# C2000_CLA_Type2_Registers register map
Vendor: Texas Instruments
Peripheral module from a debugger description file (folder C2000).
Address unit: 16 bits
Registers are 16-bit, access not given, reset 0x0 unless marked. A register's access mark holds for its fields unless they carry their own. Offsets are as the file gives them; lines under a group give offsets from that group; [hi:lo] are bit positions; {n}, {i} and the like mark numbered series; 'fields as' and 'values as' point back to an identical list; <NAME> marks a mode.

## CLA2 — CLA2 Registers
0x00 MVECT1 reset not defined — Task 1 vector
0x01 MVECT2 reset not defined — Task 2 vector
0x02 MVECT3 reset not defined — Task 3 vector
0x03 MVECT4 reset not defined — Task 4 vector
0x04 MVECT5 reset not defined — Task 5 vector
0x05 MVECT6 reset not defined — Task 6 vector
0x06 MVECT7 reset not defined — Task 7 vector
0x07 MVECT8 reset not defined — Task 8 vector
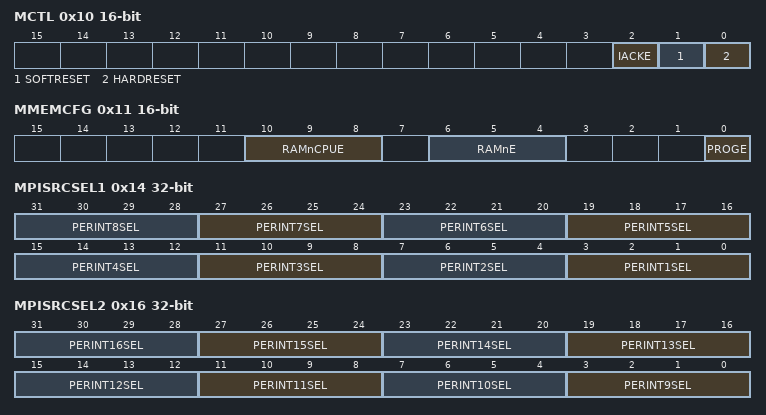
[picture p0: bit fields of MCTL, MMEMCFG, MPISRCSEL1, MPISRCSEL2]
0x10 MCTL rw — CLA control
  [2] IACKE — IACK enable
  [1] SOFTRESET
  [0] HARDRESET
0x11 MMEMCFG rw — CLA memory configuration
  [10:8] RAMnCPUE — Data RAM CPU Access Enable
  [6:4] RAMnE — Data RAM Enable
  [0] PROGE — Program memory enable
0x14 MPISRCSEL1 32-bit rw — CLA interrupt source select 1
  [4n-1:4n-4] PERINT{n}SEL (n=1..8) — Task {n} Peripheral Interrupt Input Select
0x16 MPISRCSEL2 32-bit rw — CLA interrupt source select 2
  [4n-33:4n-36] PERINT{n}SEL (n=9..16) — Task {n} Peripheral Interrupt Input Select
0x1B MVECTBGRNDACTIVE ro — Active register for MVECTBGRND
  [15:0] i16 — Active register for the Background Task Vector
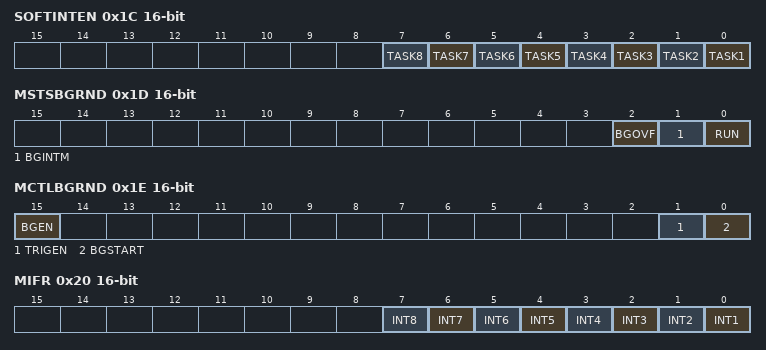
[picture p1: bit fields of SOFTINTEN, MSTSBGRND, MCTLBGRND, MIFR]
0x1C SOFTINTEN rw — CLA Software Interrupt Enable Register
  [n-1] TASK{n} (n=1..8) — Configure Software Interrupt or End of Task {n} interrupt
0x1D MSTSBGRND ro — Status register for the background task
  [2] BGOVF — Background task hardware trigger overflow
  [1] BGINTM — Indicates whether background task can be interrupted
  [0] RUN — Background task run status bit
0x1E MCTLBGRND rw — Control register for the background task
  [15] BGEN — Enable Background task
  [1] TRIGEN — Background task hardware trigger enable
  [0] BGSTART — Background task start bit
0x1F MVECTBGRND rw — Vector for the background task
  [15:0] i16 — Background task vector
0x20 MIFR ro — CLA interrupt flag
  [n-1] INT{n} (n=1..8) — Interrupt {n} flag bit
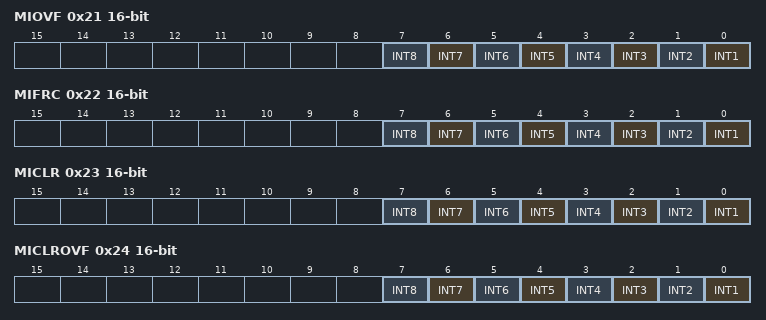
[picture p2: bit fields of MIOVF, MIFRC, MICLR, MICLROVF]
0x21 MIOVF ro — CLA interrupt overflow flag
  [n-1] INT{n} (n=1..8) — Interrupt {n} overflow bit
0x22 MIFRC rw — CLA interrupt force
  [n-1] INT{n} (n=1..8) — Interrupt {n} force bit
0x23 MICLR rw — CLA interrupt flag clear
  [n-1] INT{n} (n=1..8) — Interrupt {n} clear bit
0x24 MICLROVF rw — CLA interrupt overflow flag clear
  [n-1] INT{n} (n=1..8) — Interrupt {n} overflow clear bit
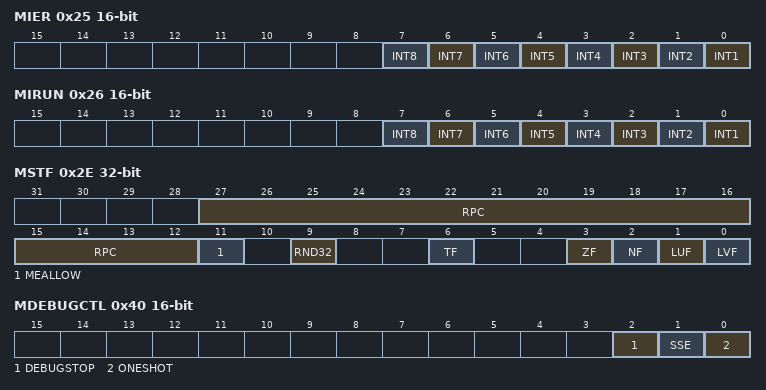
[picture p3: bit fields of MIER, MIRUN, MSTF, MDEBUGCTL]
0x25 MIER rw — CLA interrupt enable
  [n-1] INT{n} (n=1..8) — Interrupt {n} enable bit
0x26 MIRUN rw — CLA interrupt run status
  [n-1] INT{n} (n=1..8) — Interrupt {n} run status
0x28 MPC reset not defined — CLA program counter
0x2A MAR0 reset not defined — CLA auxiliary register 0
0x2B MAR1 reset not defined — CLA auxiliary register 1
0x2E MSTF 32-bit ro — CLA floating-point status register
  [27:12] RPC — Return PC
  [11] MEALLOW — Protected write
  [9] RND32 — Rounding mode
  [6] TF — Test flag
  [3] ZF — Zero flag
  [2] NF — Negative flag
  [1] LUF — Underflow flag
  [0] LVF — Overflow flag
{0x30+4i} MR{i} 32-bit reset not defined (i=0..3) — CLA result register {i}
0x40 MDEBUGCTL access per field — CLA Debug Control Register
  [2] DEBUGSTOP ro — Debug stop bit
  [1] SSE rw — Single Step Enable bit
  [0] ONESHOT rw — One Shot Mode bit
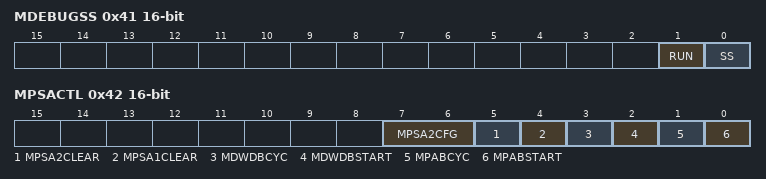
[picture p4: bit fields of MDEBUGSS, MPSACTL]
0x41 MDEBUGSS rw — CLA Debug Step Register
  [1] RUN — Run bit
  [0] SS — Single Step Command bit
0x42 MPSACTL rw — PSA Control Register
  [7:6] MPSA2CFG — PSA2 Polynomial Configuration
  [5] MPSA2CLEAR — PSA2 Clear
  [4] MPSA1CLEAR — PSA1 Clear
  [3] MDWDBCYC — DWDB logging into PSA2 is on every cycle
  [2] MDWDBSTART — Start logging DWDB onto PSA2
  [1] MPABCYC — PAB logging into PSA1 is on every cycle or when PAB changes
  [0] MPABSTART — Start logging PAB onto PSA1
0x44 MPSA1 32-bit reset not defined — CLA PSA1 Register
0x46 MPSA2 32-bit reset not defined — CLA PSA2 Register
